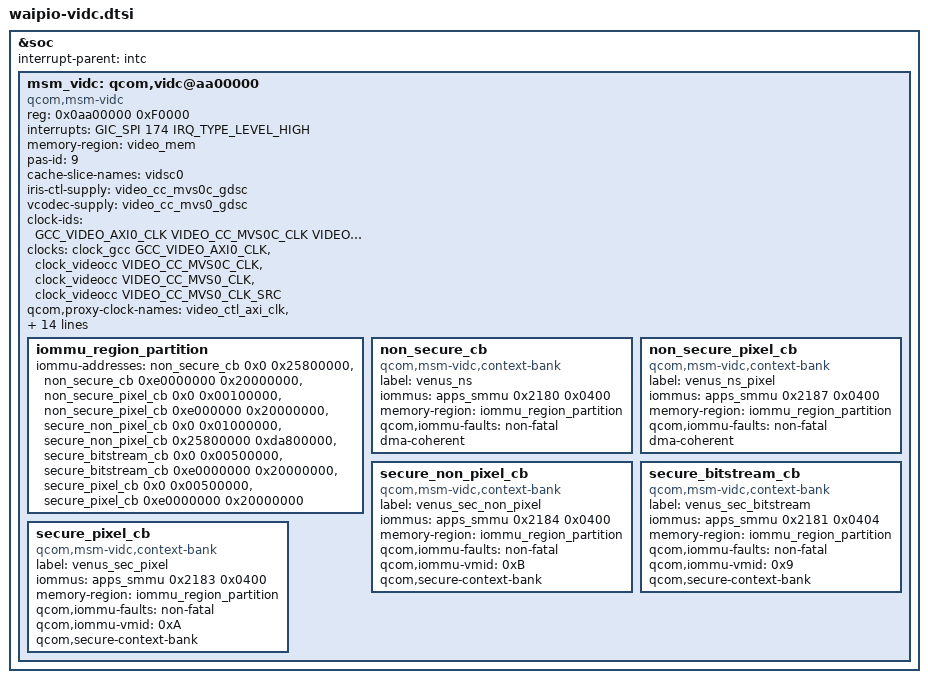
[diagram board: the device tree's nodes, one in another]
&soc {
	interrupt-parent = <&intc>;
	#address-cells = <1>;
	#size-cells = <1>;

	msm_vidc: qcom,vidc@aa00000 {
		compatible = "qcom,msm-vidc", "qcom,msm-vidc-waipio", "qcom,msm-vidc-iris2";
		status = "okay";
		reg = <0x0aa00000 0xF0000>;
		interrupts = <GIC_SPI 174 IRQ_TYPE_LEVEL_HIGH>;

		memory-region = <&video_mem>;
		pas-id = <9>;

		/* IOMMU Config */
		#address-cells = <1>;
		#size-cells = <1>;

		/* LLCC Cache */
		cache-slice-names = "vidsc0";

		/* Supply */
		iris-ctl-supply = <&video_cc_mvs0c_gdsc>;
		vcodec-supply = <&video_cc_mvs0_gdsc>;

		/* Clocks */
		clock-names = "video_ctl_axi_clk",
			"core_clk", "vcodec_clk", "video_cc_mvs0_clk_src";
		clock-ids = <GCC_VIDEO_AXI0_CLK VIDEO_CC_MVS0C_CLK
			VIDEO_CC_MVS0_CLK VIDEO_CC_MVS0_CLK_SRC>;
		clocks = <&clock_gcc GCC_VIDEO_AXI0_CLK>,
			<&clock_videocc VIDEO_CC_MVS0C_CLK>,
			<&clock_videocc VIDEO_CC_MVS0_CLK>,
			<&clock_videocc VIDEO_CC_MVS0_CLK_SRC>;
		qcom,proxy-clock-names = "video_ctl_axi_clk",
			"core_clk", "vcodec_clk", "video_cc_mvs0_clk_src";
		/* Mask: Bit0: Clock Scaling, Bit1: Mem Retention*/
		qcom,clock-configs = <0x0 0x0 0x0 0x1>;
		qcom,allowed-clock-rates = <239999999 338000000
			366000000 444000000>;
		resets = <&clock_gcc GCC_VIDEO_AXI0_CLK_ARES>,
			<&clock_videocc VIDEO_CC_MVS0C_CLK_ARES>;
		reset-names = "video_axi_reset", "video_core_reset";

		qcom,reg-presets = <0xB0088 0x0 0x11>;

		/* Video Firmware ELF image name */
		vidc,firmware-name = "vpu20_4v";

		/* Bus Interconnects */
		interconnect-names = "venus-cnoc", "venus-ddr", "venus-llcc";
		interconnects = <&gem_noc MASTER_APPSS_PROC
					&config_noc SLAVE_VENUS_CFG>,
				<&mc_virt MASTER_LLCC
					&mc_virt SLAVE_EBI1>,
				<&mmss_noc MASTER_VIDEO_P0
					&gem_noc SLAVE_LLCC>;
		/* Bus BW range (low, high) for each bus */
		qcom,bus-range-kbps = <1000 1000
					1000 15000000
					1000 15000000>;

		/* MMUs */
		iommu_region_partition: iommu_region_partition {
			/* These IOVA regions are unique per context bank */
			iommu-addresses =
				<&non_secure_cb 0x0 0x25800000>,
					<&non_secure_cb 0xe0000000 0x20000000>,
				<&non_secure_pixel_cb 0x0 0x00100000>,
					<&non_secure_pixel_cb 0xe000000 0x20000000>,
				<&secure_non_pixel_cb 0x0 0x01000000>,
					<&secure_non_pixel_cb 0x25800000 0xda800000>,
				<&secure_bitstream_cb 0x0 0x00500000>,
					<&secure_bitstream_cb 0xe0000000 0x20000000>,
				<&secure_pixel_cb 0x0 0x00500000>,
					<&secure_pixel_cb 0xe0000000 0x20000000>;
		};

		non_secure_cb: non_secure_cb {
			compatible = "qcom,msm-vidc,context-bank";
			label = "venus_ns";
			iommus = <&apps_smmu 0x2180 0x0400>;
			memory-region = <&iommu_region_partition>;
			qcom,iommu-faults = "non-fatal";
			dma-coherent;
		};

		non_secure_pixel_cb: non_secure_pixel_cb {
			compatible = "qcom,msm-vidc,context-bank";
			label = "venus_ns_pixel";
			iommus = <&apps_smmu 0x2187 0x0400>;
			memory-region = <&iommu_region_partition>;
			qcom,iommu-faults = "non-fatal";
			dma-coherent;
		};

		secure_non_pixel_cb: secure_non_pixel_cb {
			compatible = "qcom,msm-vidc,context-bank";
			label = "venus_sec_non_pixel";
			iommus = <&apps_smmu 0x2184 0x0400>;
			memory-region = <&iommu_region_partition>;
			qcom,iommu-faults = "non-fatal";
			qcom,iommu-vmid = <0xB>; /* VMID_CP_NON_PIXEL */
			qcom,secure-context-bank;
		};

		secure_bitstream_cb: secure_bitstream_cb {
			compatible = "qcom,msm-vidc,context-bank";
			label = "venus_sec_bitstream";
			iommus = <&apps_smmu 0x2181 0x0404>;
			memory-region = <&iommu_region_partition>;
			qcom,iommu-faults = "non-fatal";
			qcom,iommu-vmid = <0x9>; /* VMID_CP_BITSTREAM */
			qcom,secure-context-bank;
		};

		secure_pixel_cb: secure_pixel_cb {
			compatible = "qcom,msm-vidc,context-bank";
			label = "venus_sec_pixel";
			iommus = <&apps_smmu 0x2183 0x0400>;
			memory-region = <&iommu_region_partition>;
			qcom,iommu-faults = "non-fatal";
			qcom,iommu-vmid = <0xA>; /* VMID_CP_PIXEL */
			qcom,secure-context-bank;
		};
	};
};
